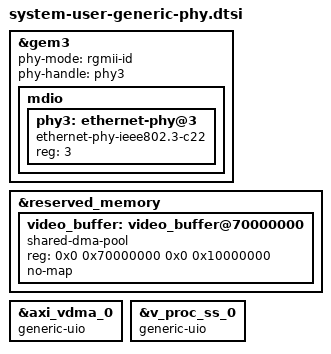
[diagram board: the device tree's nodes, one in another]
/include/ "system-conf.dtsi"
/ {
};

/* ============================================================
 * GEM3 以太网配置 - 通用PHY驱动版本
 * 
 * 使用场景：当Micrel特定驱动有问题时，使用通用PHY驱动
 * ============================================================ */
&gem3 {
    status = "okay";
    phy-mode = "rgmii-id";
    phy-handle = <&phy3>;
    
    mdio: mdio {
        #address-cells = <1>;
        #size-cells = <0>;
        
        /* 使用通用PHY兼容性字符串 */
        phy3: ethernet-phy@3 {
            reg = <3>;
            /* 只使用通用兼容性，不指定具体芯片 */
            compatible = "ethernet-phy-ieee802.3-c22";
        };
    };
};

/* ============================================================
 * 保留内存配置 - 用于视频帧缓冲
 * ============================================================ */
&reserved_memory {
    #address-cells = <2>;
    #size-cells = <2>;
    ranges;
    
    video_buffer: video_buffer@70000000 {
        compatible = "shared-dma-pool";
        reg = <0x0 0x70000000 0x0 0x10000000>;
        no-map;
    };
};

/* ============================================================
 * VDMA 配置 - 使用UIO驱动
 * ============================================================ */
&axi_vdma_0 {
    compatible = "generic-uio";
    status = "okay";
};

/* ============================================================
 * VPSS 配置 - 使用UIO驱动
 * ============================================================ */
&v_proc_ss_0 {
    compatible = "generic-uio";
    status = "okay";
};
